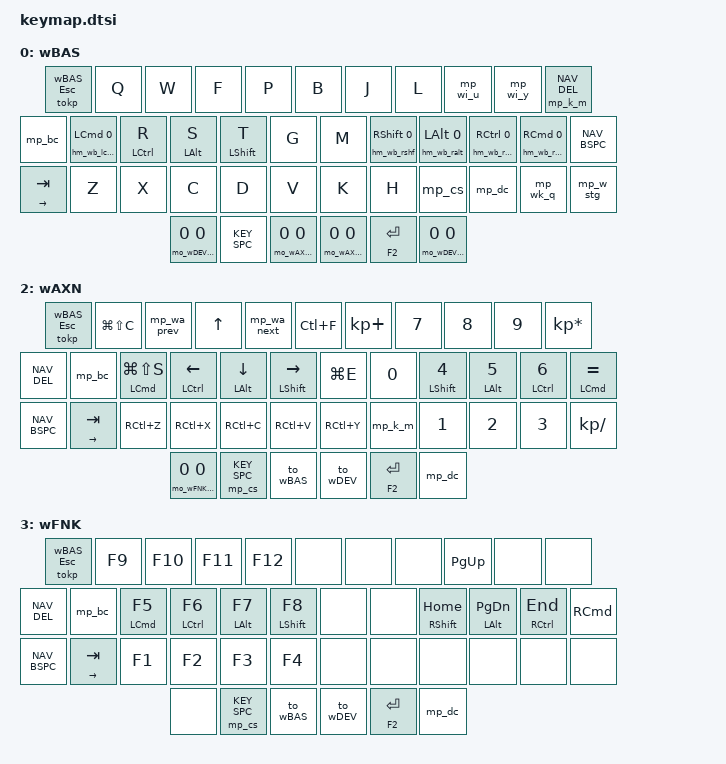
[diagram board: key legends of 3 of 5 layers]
/* Layers */
#define H_wCWR  F18
#define F_wBAS  F19
#define F_wDEV  F20
#define F_wAXN  F21
#define F_wFNK  F22
#define F_wSTG  F23

/* Shared Keys */
#define WKY_ESC  &tokp wBAS   ESC  // tap: esc    | long-tap: BAS layer
#define KEY_RET  &mt   F2     RET  // tap: return | long-tap: rename (like macOs)
#define KEY_TAB  &mt   RIGHT  TAB  // tap: tab    | long-tap: right (terminal autocompletion)

/ {
    behaviors {
        #include "morph/layers.dtsi"
        #include "morph/base.dtsi"
        #include "morph/int.dtsi"
        #include "morph/actions.dtsi"
        #include "morph/dev.dtsi"

        #include "hold/base.dtsi"
        #include "hold/dev.dtsi"
    };

    combos {
        compatible = "zmk,combos";

        #include "combos/base.dtsi"
        #include "combos/help.dtsi"
    };

    macros {
        #include "macros/layers.dtsi"
        #include "macros/int.dtsi"
        #include "macros/dev.dtsi"
    };

    keymap {
        compatible = "zmk,keymap";

        win_base_layer {
            #define WB13  &hm_wb_lcmd  LCMD   0  //A
            #define WB14  &hm LCTRL    R
            #define WB15  &hm LALT     S
            #define WB16  &hm LSHFT    T

            #define WB19  &hm_wb_rshf  RSHFT  0  //N
            #define WB20  &hm_wb_ralt  LALT   0  //E
            #define WB21  &hm_wb_rctrl RCTRL  0  //I
            #define WB22  &hm_wb_rcmd  RCMD   0  //O

            #define WB35  &mp_w_stg

            #define WB36  &mo_wDEVwBAS_to_wDEV  0 0
            #define WB38  &mo_wAXNwBAS_to_wAXN  0 0
            #define WB39  &mo_wAXNwBAS_to_wFNK  0 0
            #define WB41  &mo_wDEVwBAS_to_wDEV  0 0

            label = "wBAS";
            bindings = <
    WKY_ESC  &kp Q  &kp W  &kp F    &kp P  &kp B             &kp J    &kp L  &mp_wi_u  &mp_wi_y   &mp_k_m    NAV_DEL
     &mp_bc   WB13   WB14   WB15     WB16  &kp G             &kp M     WB19      WB20      WB21      WB22   NAV_BSPC
    KEY_TAB  &kp Z  &kp X  &kp C    &kp D  &kp V             &kp K    &kp H    &mp_cs    &mp_dc  &mp_wk_q       WB35
                            WB36  KEY_SPC   WB38              WB39  KEY_RET      WB41
            >;
        };

        win_dev_layer {
            #define WD13  &hm_wd_lcmd  LCMD    0
            #define WD14  &hm          LCTRL   LBRC
            #define WD15  &hm          LALT    RBRC
            #define WD16  &hm_wd_lshf  LSHFT   0

            #define WD19  &hm_wd_rshf  RSHFT   0
            #define WD20  &hm_wd_ralt  LALT    0
            #define WD21  &hm_wd_rctrl RCTRL   0
            #define WD22  &hm_wd_rcmd  RCMD    0

            #define WD38  &mo_wAXNwDEV_to_wBAS  0 0
            #define WD39  &mo_wAXNwDEV_to_wAXN  0 0

            label = "wDEV";
            bindings = <
    WKY_ESC     &kp AT  &mp_wd_pound  &mp_wd_money  &mp_wd_p    &m_wi_d             &m_wi_t   &mp_wd_m   &kp UNDER   &kp PRCNT    &m_wi_c   NAV_DEL
     &mp_bc       WD13          WD14          WD15      WD16    &m_wi_s             &m_wi_g       WD19        WD20        WD21       WD22  NAV_BSPC
    KEY_TAB  &kp LC(R)      &kp LPAR      &kp RPAR  &mp_wd_a   &kp BSLH            &mp_wd_s  &mp_wd_qs   &mp_wd_lt   &mp_wd_gt  &mp_wd_ql   &kp F12
                                            &mp_cs   KEY_SPC       WD38                WD39    KEY_RET      &mp_dc
            >;
        };

        win_act_num_layer {
            #define WA01  &kp LG(LS(C))           // tap: color picker
            #define WA05  &kp LC(F)               // tap: find
            #define WA13  &hm LCMD   LG(LS(S))    // tap: printscreen
            #define WA14  &hm LCTRL  LEFT
            #define WA15  &hm LALT   DOWN
            #define WA16  &hm LSHFT  RIGHT
            #define WA17  &kp LG(E)               // tap: file explorer

            #define WA19  &hm LSHFT  N4
            #define WA20  &hm LALT   N5
            #define WA21  &hm LCTRL  N6
            #define WA22  &hm LCMD   EQUAL

            #define WA35 &mo_wFNKwAXN_to_wFNK    0 0

            #define WA38  &to_wBAS
            #define WA39  &to_wDEV

            #define KEY_UNDO    &kp RC(Z)       // tap: undo
            #define KEY_REDO    &kp RC(Y)       // tap: redo
            #define KEY_CUT     &kp RC(X)       // tap: cut
            #define KEY_COPY    &kp RC(C)       // tap: copy
            #define KEY_PASTE   &kp RC(V)       // tap: paste     | shift: paste without format

            label = "wAXN";
            bindings = <
    WKY_ESC      WA01  &mp_wa_prev    &kp UP  &mp_wa_next      WA05            &kp KP_PLUS   &kp N7  &kp N8  &kp N9  &kp KP_MULTIPLY   NAV_DEL
     &mp_bc      WA13         WA14      WA15         WA16      WA17                 &kp N0     WA19    WA20    WA21             WA22  NAV_BSPC
    KEY_TAB  KEY_UNDO      KEY_CUT  KEY_COPY    KEY_PASTE  KEY_REDO                &mp_k_m   &kp N1  &kp N2  &kp N3    &kp KP_DIVIDE      WA35
                                      &mp_cs      KEY_SPC      WA38                   WA39  KEY_RET  &mp_dc
            >;
        };

        win_functions_layer {
            #define WK13  &hm LCMD   F5
            #define WK14  &hm LCTRL  F6
            #define WK15  &hm LALT   F7
            #define WK16  &hm LSHFT  F8

            #define WK19  &hm RSHFT  HOME
            #define WK20  &hm LALT   PG_DN
            #define WK21  &hm RCTRL  END
            #define WK22  &kp RCMD

            #define WK38  &to_wBAS
            #define WK39  &to_wDEV

            label = "wFNK";
            bindings = <
    WKY_ESC  &kp F9  &kp F10  &kp F11  &kp F12  &none                  &none    &none  &kp PG_UP    &none    &none   NAV_DEL
     &mp_bc    WK13     WK14     WK15     WK16  &none                  &none     WK19       WK20     WK21     WK22  NAV_BSPC
    KEY_TAB  &kp F1   &kp F2   &kp F3   &kp F4  &none                  &none    &none      &none    &none    &none     &none
                               &mp_cs  KEY_SPC   WK38                   WK39  KEY_RET     &mp_dc
            >;
        };

        win_settings_layer {
            #define WS10  &kp LG(LS(GRAVE))    // tap: fancy zones
            #define WS11  &kp LC(LS(ESC))      // tap: task manager
            #define WS24  &kp LG(K)            // tap: connect quick action

            #define WS22  &kp RG(PAUSE_BREAK)  // tap: system info
            #define WS23  &kp RG(I)            // tap: windows settings
            #define WS34  &kp LC(LA(DEL))      // tap: windows security

            #define WS05  &kp RC(PLUS)         // tap: zoom in
            #define WS17  &kp RC(N0)           // tap: zoom reset
            #define WS29  &kp RC(MINUS)        // tap: zoom out

            #define WS07  &kp RG(EQUAL)        // tap: magnifier in
            #define WS18  &kp RG(ESC)          // tap: magnifier reset
            #define WS30  &kp RG(MINUS)        // tap: magnifier out

            label = "wSTG";
            bindings = <
       WKY_ESC  &to wBAS  &m_s_b1       &m_s_b2    &none       WS05                   WS07  &kp C_VOL_DN    &kp C_MUTE  &kp C_VOL_UP  WS10   WS11
    &bt BT_CLR     &none  &m_s_b3       &m_s_b4    &none       WS17                   WS18    &kp C_PREV      &kp C_PP    &kp C_NEXT  WS22   WS23
          WS24  &to aBAS  &m_s_b5       &m_s_b6    &none       WS29                   WS30      &kp C_RW    &kp C_STOP      &kp C_FF  WS34  &none
                                   &kp C_BRI_DN  KEY_SPC   &to_wBAS               &to_wDEV       KEY_RET  &kp C_BRI_UP
            >;
        };
    };
};
